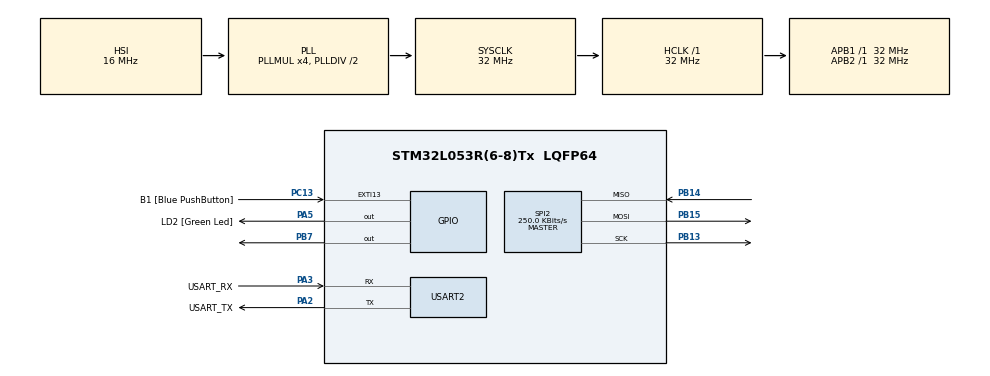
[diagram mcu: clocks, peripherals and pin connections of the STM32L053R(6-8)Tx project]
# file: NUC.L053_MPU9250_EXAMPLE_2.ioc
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Mcu.Family=STM32L0
Mcu.Name=STM32L053R(6-8)Tx
Mcu.Package=LQFP64
PA13.GPIO_Label=TMS
PA13.Signal=SYS_SWDIO
PA14.GPIO_Label=TCK
PA14.Signal=SYS_SWCLK
PA2.GPIO_Label=USART_TX
PA2.Mode=Asynchronous
PA2.Signal=USART2_TX
PA3.GPIO_Label=USART_RX
PA3.Mode=Asynchronous
PA3.Signal=USART2_RX
PA5.GPIO_Label=LD2 [Green Led]
PA5.Signal=GPIO_Output
PB13.Mode=Full_Duplex_Master
PB13.Signal=SPI2_SCK
PB14.Mode=Full_Duplex_Master
PB14.Signal=SPI2_MISO
PB15.Mode=Full_Duplex_Master
PB15.Signal=SPI2_MOSI
PB7.Signal=GPIO_Output
PC13.GPIO_Label=B1 [Blue PushButton]
PC13.GPIO_ModeDefaultEXTI=GPIO_MODE_IT_FALLING
PC13.Signal=GPXTI13
PC14-OSC32_IN.Signal=RCC_OSC32_IN
PC15-OSC32_OUT.Signal=RCC_OSC32_OUT
PH0-OSC_IN.Signal=RCC_OSC_IN
PH1-OSC_OUT.Signal=RCC_OSC_OUT
ProjectManager.HeapSize=0x200
ProjectManager.StackSize=0x400
ProjectManager.TargetToolchain=STM32CubeIDE
RCC.AHBFreq_Value=32000000
RCC.APB1Freq_Value=32000000
RCC.APB1TimFreq_Value=32000000
RCC.APB2Freq_Value=32000000
RCC.APB2TimFreq_Value=32000000
RCC.HCLKFreq_Value=32000000
RCC.HSE_VALUE=8000000
RCC.HSI16_VALUE=16000000
RCC.HSI48_VALUE=48000000
RCC.HSI_VALUE=16000000
RCC.LSEState=RCC_LSE_ON
RCC.LSE_VALUE=32768
RCC.MSI_VALUE=2097000
RCC.PLLMUL=RCC_PLLMUL_4
RCC.SYSCLKFreq_VALUE=32000000
RCC.SYSCLKSource=RCC_SYSCLKSOURCE_PLLCLK
RCC.VCOOutputFreq_Value=64000000
SPI2.BaudRatePrescaler=SPI_BAUDRATEPRESCALER_128
SPI2.CLKPhase=SPI_PHASE_2EDGE
SPI2.CLKPolarity=SPI_POLARITY_HIGH
SPI2.CalculateBaudRate=250.0 KBits/s
SPI2.Direction=SPI_DIRECTION_2LINES
SPI2.Mode=SPI_MODE_MASTER
SPI2.VirtualType=VM_MASTER
USART2.VirtualMode-Asynchronous=VM_ASYNC
board=NUCLEO-L053R8

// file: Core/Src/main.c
/* USER CODE BEGIN Header */
/**
  ******************************************************************************
  * @file           : main.c
  * @brief          : Main program body
  ******************************************************************************
  * @attention
  *
  * Copyright (c) 2023 STMicroelectronics.
  * All rights reserved.
  *
  * This software is licensed under terms that can be found in the LICENSE file
  * in the root directory of this software component.
  * If no LICENSE file comes with this software, it is provided AS-IS.
  *
  ******************************************************************************
  */
/* USER CODE END Header */
#include "main.h"
#include "spi.h"
#include "usart.h"
#include "gpio.h"

/* USER CODE BEGIN Includes */
#include"MPU9250.h"
/* USER CODE END Includes */

/* USER CODE BEGIN PTD */
uint16_t Acc[3],Gyro[3],Mag[3];
float temp;
int16_t acc_total_vector;
/* USER CODE END PTD */

/* USER CODE BEGIN PV */
	  int16_t AccData[3], GyroData[3], MagData[3];

/* USER CODE END PV */

void SystemClock_Config(void);

int main(void)
{

  /* MCU Configuration--------------------------------------------------------*/

  /* Reset of all peripherals, Initializes the Flash interface and the Systick. */
  HAL_Init();

  /* Configure the system clock */
  SystemClock_Config();

  /* Initialize all configured peripherals */
  MX_GPIO_Init();
  MX_SPI2_Init();
  MX_USART2_UART_Init();

  /* Infinite loop */
  /* USER CODE BEGIN WHILE */
  while (1)
  {
	  MPU9250_GetData(Acc,Mag,Gyro,&temp);

	  	  HAL_Delay(1000);

    /* USER CODE END WHILE */

  }
}

void SystemClock_Config(void)
{
  RCC_OscInitTypeDef RCC_OscInitStruct = {0};
  RCC_ClkInitTypeDef RCC_ClkInitStruct = {0};
  RCC_PeriphCLKInitTypeDef PeriphClkInit = {0};

  /** Configure the main internal regulator output voltage
  */
  __HAL_PWR_VOLTAGESCALING_CONFIG(PWR_REGULATOR_VOLTAGE_SCALE1);

  /** Initializes the RCC Oscillators according to the specified parameters
  * in the RCC_OscInitTypeDef structure.
  */
  RCC_OscInitStruct.OscillatorType = RCC_OSCILLATORTYPE_HSI;
  RCC_OscInitStruct.HSIState = RCC_HSI_ON;
  RCC_OscInitStruct.HSICalibrationValue = RCC_HSICALIBRATION_DEFAULT;
  RCC_OscInitStruct.PLL.PLLState = RCC_PLL_ON;
  RCC_OscInitStruct.PLL.PLLSource = RCC_PLLSOURCE_HSI;
  RCC_OscInitStruct.PLL.PLLMUL = RCC_PLLMUL_4;
  RCC_OscInitStruct.PLL.PLLDIV = RCC_PLLDIV_2;
  if (HAL_RCC_OscConfig(&RCC_OscInitStruct) != HAL_OK)
  {
    Error_Handler();
  }

  /** Initializes the CPU, AHB and APB buses clocks
  */
  RCC_ClkInitStruct.ClockType = RCC_CLOCKTYPE_HCLK|RCC_CLOCKTYPE_SYSCLK
                              |RCC_CLOCKTYPE_PCLK1|RCC_CLOCKTYPE_PCLK2;
  RCC_ClkInitStruct.SYSCLKSource = RCC_SYSCLKSOURCE_PLLCLK;
  RCC_ClkInitStruct.AHBCLKDivider = RCC_SYSCLK_DIV1;
  RCC_ClkInitStruct.APB1CLKDivider = RCC_HCLK_DIV1;
  RCC_ClkInitStruct.APB2CLKDivider = RCC_HCLK_DIV1;

  if (HAL_RCC_ClockConfig(&RCC_ClkInitStruct, FLASH_LATENCY_1) != HAL_OK)
  {
    Error_Handler();
  }
  PeriphClkInit.PeriphClockSelection = RCC_PERIPHCLK_USART2;
  PeriphClkInit.Usart2ClockSelection = RCC_USART2CLKSOURCE_PCLK1;
  if (HAL_RCCEx_PeriphCLKConfig(&PeriphClkInit) != HAL_OK)
  {
    Error_Handler();
  }
}

void Error_Handler(void)
{
  __disable_irq();
  while (1)
  {
  }
}
